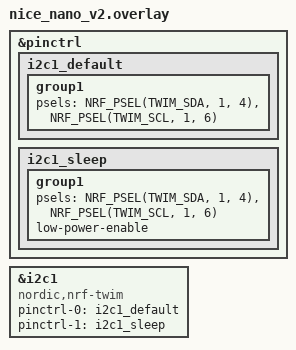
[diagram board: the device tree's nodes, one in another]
&pinctrl {

    i2c1_default: i2c1_default {
        group1 {
            psels = <NRF_PSEL(TWIM_SDA, 1, 4)>,
                    <NRF_PSEL(TWIM_SCL, 1, 6)>;
        };
    };

    i2c1_sleep: i2c1_sleep {
        group1 {
            psels = <NRF_PSEL(TWIM_SDA, 1, 4)>,
                    <NRF_PSEL(TWIM_SCL, 1, 6)>;
            low-power-enable;
        };
    };
};


&i2c1 {
    status = "okay";
    compatible = "nordic,nrf-twim";
    pinctrl-0 = <&i2c1_default>;
    pinctrl-1 = <&i2c1_sleep>;
    pinctrl-names = "default", "sleep";
};

